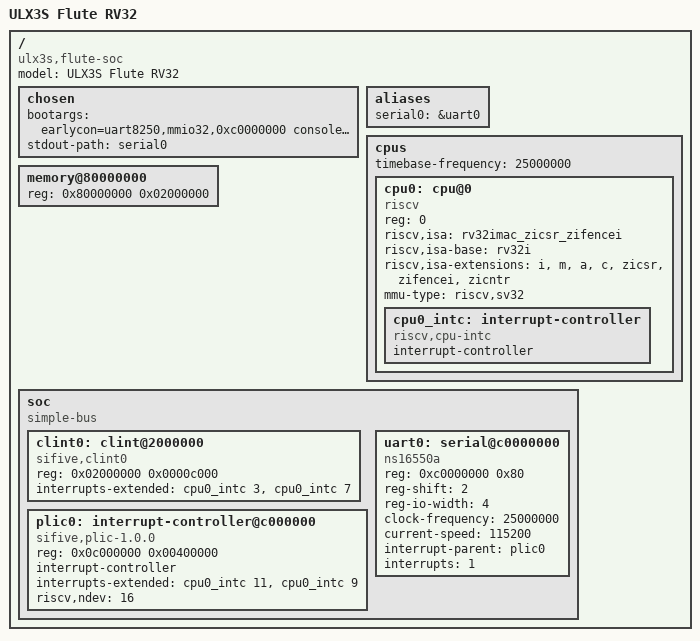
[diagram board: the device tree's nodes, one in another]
// ULX3S Flute SoC: RV32IMAC (+S, U, Sv32, PMP), 32 MB SDRAM, CLINT, PLIC (2 contexts), 16550 UART.
// Map: Flute/src_Testbench/SoC/SoC_Map.bsv.  mtime ticks once per core clock (25 MHz board clock
// by default; 32.142857 MHz with SYS_PLL=1).
/dts-v1/;

/ {
	#address-cells = <1>;
	#size-cells = <1>;
	compatible = "ulx3s,flute-soc";
	model = "ULX3S Flute RV32";

	chosen {
		bootargs = "earlycon=uart8250,mmio32,0xc0000000 console=ttyS0 loglevel=8";
		stdout-path = "serial0";
	};

	aliases {
		serial0 = &uart0;
	};

	cpus {
		#address-cells = <1>;
		#size-cells = <0>;
		timebase-frequency = <25000000>;

		cpu0: cpu@0 {
			device_type = "cpu";
			reg = <0>;
			status = "okay";
			compatible = "riscv";
			riscv,isa = "rv32imac_zicsr_zifencei";
			riscv,isa-base = "rv32i";
			riscv,isa-extensions = "i", "m", "a", "c", "zicsr", "zifencei", "zicntr";
			mmu-type = "riscv,sv32";

			cpu0_intc: interrupt-controller {
				#interrupt-cells = <1>;
				compatible = "riscv,cpu-intc";
				interrupt-controller;
			};
		};
	};

	memory@80000000 {
		device_type = "memory";
		reg = <0x80000000 0x02000000>;
	};

	soc {
		#address-cells = <1>;
		#size-cells = <1>;
		compatible = "simple-bus";
		ranges;

		clint0: clint@2000000 {
			compatible = "sifive,clint0", "riscv,clint0";
			reg = <0x02000000 0x0000c000>;
			interrupts-extended = <&cpu0_intc 3>, <&cpu0_intc 7>;
		};

		plic0: interrupt-controller@c000000 {
			compatible = "sifive,plic-1.0.0", "riscv,plic0";
			reg = <0x0c000000 0x00400000>;
			#address-cells = <0>;
			#interrupt-cells = <1>;
			interrupt-controller;
			interrupts-extended = <&cpu0_intc 11>, <&cpu0_intc 9>;
			riscv,ndev = <16>;
		};

		uart0: serial@c0000000 {
			compatible = "ns16550a";
			reg = <0xc0000000 0x80>;
			reg-shift = <2>;
			reg-io-width = <4>;
			clock-frequency = <25000000>;
			current-speed = <115200>;
			interrupt-parent = <&plic0>;
			interrupts = <1>;
		};
	};
};
